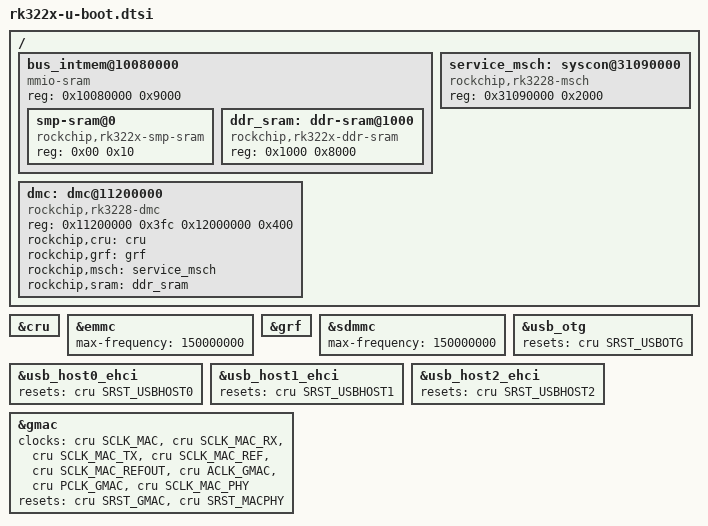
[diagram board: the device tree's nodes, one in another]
// SPDX-License-Identifier: GPL-2.0+

#include "rockchip-u-boot.dtsi"

/ {
	bus_intmem@10080000 {
		compatible = "mmio-sram";
		reg = <0x10080000 0x9000>;
		#address-cells = <1>;
		#size-cells = <1>;
		ranges = <0 0x10080000 0x9000>;

		smp-sram@0 {
			compatible = "rockchip,rk322x-smp-sram";
			reg = <0x00 0x10>;
		};

		ddr_sram: ddr-sram@1000 {
			compatible = "rockchip,rk322x-ddr-sram";
			reg = <0x1000 0x8000>;
		};
	};

	dmc: dmc@11200000 {
		compatible = "rockchip,rk3228-dmc", "syscon";
		reg = <0x11200000 0x3fc
		       0x12000000 0x400>;
		rockchip,cru = <&cru>;
		rockchip,grf = <&grf>;
		rockchip,msch = <&service_msch>;
		rockchip,sram = <&ddr_sram>;
		bootph-all;
	};

	service_msch: syscon@31090000 {
		compatible = "rockchip,rk3228-msch", "syscon";
		reg = <0x31090000 0x2000>;
		bootph-all;
	};
};

&cru {
	bootph-all;
};

&emmc {
	max-frequency = <150000000>;
};

&grf {
	bootph-all;
};

&sdmmc {
	max-frequency = <150000000>;
};

/*
 * The dwc2/ehci drivers need the reset lines of the USB controllers.  Linux
 * does not, so they are added here instead of to the imported Linux DT.
 */
&usb_otg {
	resets = <&cru SRST_USBOTG>;
	reset-names = "dwc2";
};

&usb_host0_ehci {
	resets = <&cru SRST_USBHOST0>;
	reset-names = "ehci";
};

&usb_host1_ehci {
	resets = <&cru SRST_USBHOST1>;
	reset-names = "ehci";
};

&usb_host2_ehci {
	resets = <&cru SRST_USBHOST2>;
	reset-names = "ehci";
};

/* The integrated 10/100 PHY needs its own clock and reset */
&gmac {
	clocks = <&cru SCLK_MAC>, <&cru SCLK_MAC_RX>,
		<&cru SCLK_MAC_TX>, <&cru SCLK_MAC_REF>,
		<&cru SCLK_MAC_REFOUT>, <&cru ACLK_GMAC>,
		<&cru PCLK_GMAC>, <&cru SCLK_MAC_PHY>;
	clock-names = "stmmaceth", "mac_clk_rx",
		"mac_clk_tx", "clk_mac_ref",
		"clk_mac_refout", "aclk_mac",
		"pclk_mac", "clk_macphy";
	resets = <&cru SRST_GMAC>, <&cru SRST_MACPHY>;
	reset-names = "stmmaceth", "mac-phy";
};
